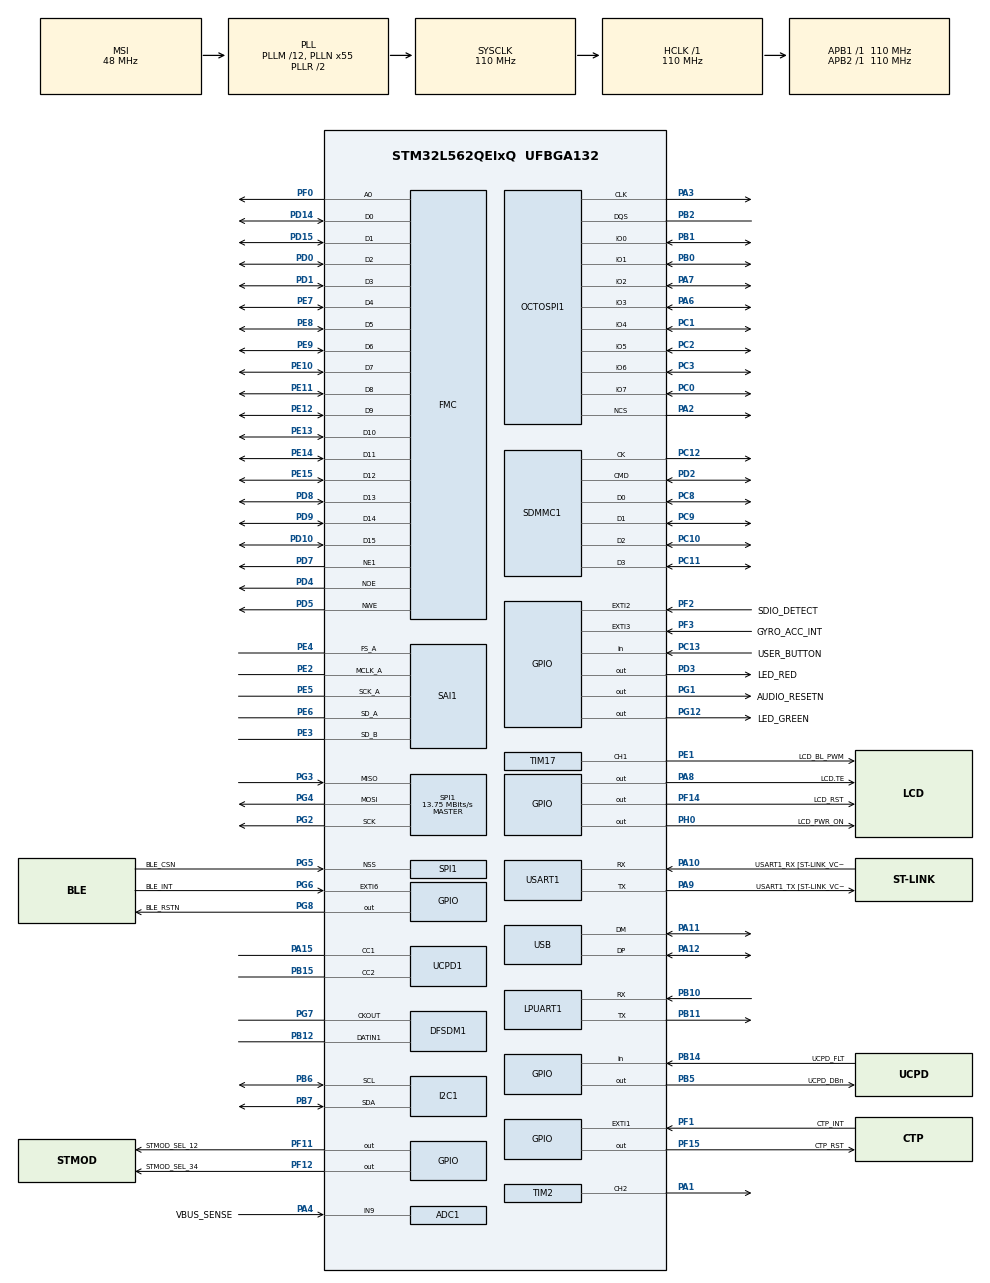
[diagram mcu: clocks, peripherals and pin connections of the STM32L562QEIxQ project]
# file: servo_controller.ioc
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ADC1.Channel-0\#ChannelRegularConversion=ADC_CHANNEL_9
ADC1.NbrOfConversionFlag=1
ADC1.OffsetNumber-0\#ChannelRegularConversion=ADC_OFFSET_NONE
ADC1.Rank-0\#ChannelRegularConversion=1
ADC1.SamplingTime-0\#ChannelRegularConversion=ADC_SAMPLETIME_2CYCLES_5
ADC1.master=1
I2C1.Timing=0x40505681
Mcu.Family=STM32L5
Mcu.Name=STM32L562QEIxQ
Mcu.Package=UFBGA132
Mcu.TrustZone=disable
NVIC.PriorityGroup=NVIC_PRIORITYGROUP_3
PA1.Signal=S_TIM2_CH2
PA10.GPIO_Label=USART1_RX [ST-LINK_VCP_TX]
PA10.Mode=Asynchronous
PA10.Signal=USART1_RX
PA11.Mode=Device
PA11.Signal=USB_DM
PA12.Mode=Device
PA12.Signal=USB_DP
PA13\ (JTMS/SWDIO).Mode=Trace_Asynchronous_SW
PA13\ (JTMS/SWDIO).Signal=DEBUG_JTMS-SWDIO
PA14\ (JTCK/SWCLK).Mode=Trace_Asynchronous_SW
PA14\ (JTCK/SWCLK).Signal=DEBUG_JTCK-SWCLK
PA15\ (JTDI).Mode=Source_AllSignals
PA15\ (JTDI).Signal=UCPD1_CC1
PA2.Mode=octods_mode
PA2.Signal=OCTOSPI1_NCS
PA3.Mode=octods_mode
PA3.Signal=OCTOSPI1_CLK
PA4.GPIO_Label=VBUS_SENSE
PA4.Signal=ADCx_IN9
PA6.Mode=octods_mode
PA6.Signal=OCTOSPI1_IO3
PA7.Mode=octods_mode
PA7.Signal=OCTOSPI1_IO2
PA8.GPIO_Label=LCD.TE
PA8.Signal=GPIO_Output
PA9.GPIO_Label=USART1_TX [ST-LINK_VCP_RX]
PA9.Mode=Asynchronous
PA9.Signal=USART1_TX
PB0.Mode=octods_mode
PB0.Signal=OCTOSPI1_IO1
PB1.Mode=octods_mode
PB1.Signal=OCTOSPI1_IO0
PB10.Mode=Asynchronous
PB10.Signal=LPUART1_RX
PB11.Mode=Asynchronous
PB11.Signal=LPUART1_TX
PB12.Signal=S_DATAIN1DFSDM1
PB14.GPIO_Label=UCPD_FLT
PB14.Signal=GPIO_Input
PB15.Mode=Source_AllSignals
PB15.Signal=UCPD1_CC2
PB2.Mode=octods_mode
PB2.Signal=OCTOSPI1_DQS
PB3\ (JTDO/TRACESWO).Mode=Trace_Asynchronous_SW
PB3\ (JTDO/TRACESWO).Signal=DEBUG_JTDO-SWO
PB5.GPIO_Label=UCPD_DBn
PB5.Signal=GPIO_Output
PB6.Mode=I2C
PB6.Signal=I2C1_SCL
PB7.Mode=I2C
PB7.Signal=I2C1_SDA
PC0.Mode=octods_mode
PC0.Signal=OCTOSPI1_IO7
PC1.Mode=octods_mode
PC1.Signal=OCTOSPI1_IO4
PC10.Mode=SD_4_bits_Wide_bus
PC10.Signal=SDMMC1_D2
PC11.Mode=SD_4_bits_Wide_bus
PC11.Signal=SDMMC1_D3
PC12.Mode=SD_4_bits_Wide_bus
PC12.Signal=SDMMC1_CK
PC13.GPIO_Label=USER_BUTTON
PC13.Signal=GPIO_Input
PC14-OSC32_IN\ (PC14).Mode=LSE-External-Oscillator
PC14-OSC32_IN\ (PC14).Signal=RCC_OSC32_IN
PC15-OSC32_OUT\ (PC15).Mode=LSE-External-Oscillator
PC15-OSC32_OUT\ (PC15).Signal=RCC_OSC32_OUT
PC2.Mode=octods_mode
PC2.Signal=OCTOSPI1_IO5
PC3.Mode=octods_mode
PC3.Signal=OCTOSPI1_IO6
PC8.Mode=SD_4_bits_Wide_bus
PC8.Signal=SDMMC1_D0
PC9.Mode=SD_4_bits_Wide_bus
PC9.Signal=SDMMC1_D1
PD0.Signal=FMC_D2_DA2
PD1.Signal=FMC_D3_DA3
PD10.Signal=FMC_D15_DA15
PD14.Signal=FMC_D0_DA0
PD15.Signal=FMC_D1_DA1
PD2.Mode=SD_4_bits_Wide_bus
PD2.Signal=SDMMC1_CMD
PD3.GPIO_Label=LED_RED
PD3.Signal=GPIO_Output
PD4.Signal=FMC_NOE
PD5.Signal=FMC_NWE
PD7.Mode=NorPsramChipSelect1_1
PD7.Signal=FMC_NE1
PD8.Signal=FMC_D13_DA13
PD9.Signal=FMC_D14_DA14
PE1.GPIO_Label=LCD_BL_PWM
PE1.Signal=S_TIM17_CH1
PE10.Signal=FMC_D7_DA7
PE11.Signal=FMC_D8_DA8
PE12.Signal=FMC_D9_DA9
PE13.Signal=FMC_D10_DA10
PE14.Signal=FMC_D11_DA11
PE15.Signal=FMC_D12_DA12
PE2.Mode=SAI_A_MasterWithClock
PE2.Signal=SAI1_MCLK_A
PE3.Mode=SAI_B_SPDIF
PE3.Signal=SAI1_SD_B
PE4.Mode=SAI_A_MasterWithClock
PE4.Signal=SAI1_FS_A
PE5.Mode=SAI_A_MasterWithClock
PE5.Signal=SAI1_SCK_A
PE6.Mode=SAI_A_MasterWithClock
PE6.Signal=SAI1_SD_A
PE7.Signal=FMC_D4_DA4
PE8.Signal=FMC_D5_DA5
PE9.Signal=FMC_D6_DA6
PF0.Signal=FMC_A0
PF1.GPIO_Label=CTP_INT
PF1.Signal=GPXTI1
PF11.GPIO_Label=STMOD_SEL_12
PF11.Signal=GPIO_Output
PF12.GPIO_Label=STMOD_SEL_34
PF12.Signal=GPIO_Output
PF14.GPIO_Label=LCD_RST
PF14.Signal=GPIO_Output
PF15.GPIO_Label=CTP_RST
PF15.Signal=GPIO_Output
PF2.GPIO_Label=SDIO_DETECT
PF2.Signal=GPXTI2
PF3.GPIO_Label=GYRO_ACC_INT
PF3.Signal=GPXTI3
PG1.GPIO_Label=AUDIO_RESETN
PG1.Signal=GPIO_Output
PG12.GPIO_Label=LED_GREEN
PG12.Signal=GPIO_Output
PG2.Mode=Full_Duplex_Master
PG2.Signal=SPI1_SCK
PG3.Mode=Full_Duplex_Master
PG3.Signal=SPI1_MISO
PG4.Mode=Full_Duplex_Master
PG4.Signal=SPI1_MOSI
PG5.GPIO_Label=BLE_CSN
PG5.Mode=NSS_Signal_Hard_Input
PG5.Signal=SPI1_NSS
PG6.GPIO_Label=BLE_INT
PG6.Signal=GPXTI6
PG7.Signal=S_CKOUTDFSDM1
PG8.GPIO_Label=BLE_RSTN
PG8.Signal=GPIO_Output
PH0-OSC_IN\ (PH0).GPIO_Label=LCD_PWR_ON
PH0-OSC_IN\ (PH0).Signal=GPIO_Output
ProjectManager.HeapSize=0x200
ProjectManager.StackSize=0x400
ProjectManager.TargetToolchain=EWARM V8.32
RCC.ADCFreq_Value=96000000
RCC.AHBFreq_Value=110000000
RCC.APB1Freq_Value=110000000
RCC.APB1TimFreq_Value=110000000
RCC.APB2Freq_Value=110000000
RCC.APB2TimFreq_Value=110000000
RCC.CK48CLockSelection=RCC_USBCLKSOURCE_MSI
RCC.CortexFreq_Value=110000000
RCC.HCLKFreq_Value=110000000
RCC.HSE_VALUE=8000000
RCC.HSI48_VALUE=48000000
RCC.HSI_VALUE=16000000
RCC.MSIClockRange=RCC_MSIRANGE_11
RCC.MSI_VALUE=48000000
RCC.PLLM=12
RCC.PLLN=55
RCC.PLLSAI1M=4
RCC.PLLSAI1N=48
RCC.PLLSAI1P=RCC_PLLP_DIV17
RCC.PLLSAI1Source=RCC_PLLSAI1SOURCE_HSI
RCC.SDMMCClockSelection=RCC_SDIOCLKSOURCE_CLK48
RCC.SYSCLKFreq_VALUE=110000000
RCC.SYSCLKSource=RCC_SYSCLKSOURCE_PLLCLK
RCC.USBFreq_Value=48000000
RCC.VCOOutputFreq_Value=220000000
SAI1.ErrorAudioFreq-SAI_A_MasterWithClock=-77.02 %
SAI1.Instance-SAI_A_MasterWithClock=SAI$Index_Block_A
SAI1.Instance-SAI_B_SPDIF=SAI$Index_Block_B
SAI1.MckOutput-SAI_A_MasterWithClock=SAI_MCK_OUTPUT_ENABLE
SAI1.RealAudioFreq-SAI_A_MasterWithClock=44.117 KHz
SAI1.RealAudioFreq-SAI_B_SPDIF=214.285 KHz
SAI1.VirtualMode-SAI_A_MasterWithClock=VM_MASTER
SAI1.VirtualMode-SAI_B_SPDIF=VM_SPDIF
SH.ADCx_IN9.0=ADC1_IN9,IN9-Single-Ended
SH.FMC_A0.0=FMC_A0,A0_1
SH.FMC_D0_DA0.0=FMC_DA0
SH.FMC_D0_DA0.1=FMC_D0,16b-d1
SH.FMC_D10_DA10.0=FMC_DA10
SH.FMC_D10_DA10.1=FMC_D10,16b-d1
SH.FMC_D11_DA11.0=FMC_DA11
SH.FMC_D11_DA11.1=FMC_D11,16b-d1
SH.FMC_D12_DA12.0=FMC_DA12
SH.FMC_D12_DA12.1=FMC_D12,16b-d1
SH.FMC_D13_DA13.0=FMC_DA13
SH.FMC_D13_DA13.1=FMC_D13,16b-d1
SH.FMC_D14_DA14.0=FMC_DA14
SH.FMC_D14_DA14.1=FMC_D14,16b-d1
SH.FMC_D15_DA15.0=FMC_DA15
SH.FMC_D15_DA15.1=FMC_D15,16b-d1
SH.FMC_D1_DA1.0=FMC_DA1
SH.FMC_D1_DA1.1=FMC_D1,16b-d1
SH.FMC_D2_DA2.0=FMC_DA2
SH.FMC_D2_DA2.1=FMC_D2,16b-d1
SH.FMC_D3_DA3.0=FMC_DA3
SH.FMC_D3_DA3.1=FMC_D3,16b-d1
SH.FMC_D4_DA4.0=FMC_DA4
SH.FMC_D4_DA4.1=FMC_D4,16b-d1
SH.FMC_D5_DA5.0=FMC_DA5
SH.FMC_D5_DA5.1=FMC_D5,16b-d1
SH.FMC_D6_DA6.0=FMC_DA6
SH.FMC_D6_DA6.1=FMC_D6,16b-d1
SH.FMC_D7_DA7.0=FMC_DA7
SH.FMC_D7_DA7.1=FMC_D7,16b-d1
SH.FMC_D8_DA8.0=FMC_DA8
SH.FMC_D8_DA8.1=FMC_D8,16b-d1
SH.FMC_D9_DA9.0=FMC_DA9
SH.FMC_D9_DA9.1=FMC_D9,16b-d1
SH.FMC_NOE.0=FMC_NOE,Lcd1
SH.FMC_NWE.0=FMC_NWE,Lcd1
SH.S_CKOUTDFSDM1.0=DFSDM1_CKOUT,CKOUT
SH.S_DATAIN1DFSDM1.0=DFSDM1_DATIN1,Manchester_input_from_ch1
SH.S_TIM17_CH1.0=TIM17_CH1,PWM Generation1 CH1
SH.S_TIM2_CH2.0=TIM2_CH2,PWM Generation2 CH2
SPI1.BaudRatePrescaler=SPI_BAUDRATEPRESCALER_8
SPI1.CalculateBaudRate=13.75 MBits/s
SPI1.Direction=SPI_DIRECTION_2LINES
SPI1.Mode=SPI_MODE_MASTER
SPI1.VirtualNSS=VM_NSSHARD
SPI1.VirtualType=VM_MASTER
TIM17.Channel=TIM_CHANNEL_1
TIM2.Channel-PWM\ Generation2\ CH2=TIM_CHANNEL_2
USART1.VirtualMode-Asynchronous=VM_ASYNC
VP_DFSDM1_VS_IN0.Mode=Parallel_Input_ch0
VP_DFSDM1_VS_IN2.Mode=Parallel_Input_ch2
VP_GTZC_VS_GTZC_Enable.Mode=GTZC_Enable
VP_PWR_VS_DBSignals.Mode=DisableDeadBatterySignals
VP_SYS_S_VS_Systick.Mode=SysTick
VP_TIM16_VS_ClockSourceINT.Mode=Enable_Timer
VP_TIM17_VS_ClockSourceINT.Mode=Enable_Timer
VP_TIM4_VS_ClockSourceITR.Mode=TriggerSource_ITR1
VP_TIM4_VS_ControllerModeClock.Mode=Clock Mode
board=STM32L562E-DK

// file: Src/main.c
/* USER CODE BEGIN Header */
/**
  ******************************************************************************
  * @file           : main.c
  * @brief          : Main program body
  ******************************************************************************
  * @attention
  *
  * <h2><center>&copy; Copyright (c) 2020 STMicroelectronics.
  * All rights reserved.</center></h2>
  *
  * This software component is licensed by ST under BSD 3-Clause license,
  * the "License"; You may not use this file except in compliance with the
  * License. You may obtain a copy of the License at:
  *                        opensource.org/licenses/BSD-3-Clause
  *
  ******************************************************************************
  */
/* USER CODE END Header */

#include "main.h"

/* USER CODE BEGIN Includes */
#include "stm32l552e_eval.h"
/* USER CODE END Includes */

ADC_HandleTypeDef hadc1;

DFSDM_Channel_HandleTypeDef hdfsdm1_channel0;
DFSDM_Channel_HandleTypeDef hdfsdm1_channel1;
DFSDM_Channel_HandleTypeDef hdfsdm1_channel2;

I2C_HandleTypeDef hi2c1;

UART_HandleTypeDef hlpuart1;
UART_HandleTypeDef huart1;

OSPI_HandleTypeDef hospi1;

SAI_HandleTypeDef hsai_BlockA1;
SAI_HandleTypeDef hsai_BlockB1;

SD_HandleTypeDef hsd1;

SPI_HandleTypeDef hspi1;

TIM_HandleTypeDef htim2;
TIM_HandleTypeDef htim4;
TIM_HandleTypeDef htim16;
TIM_HandleTypeDef htim17;

PCD_HandleTypeDef hpcd_USB_FS;

SRAM_HandleTypeDef hsram1;

void        SystemClock_Config(void);
void        PeriphCommonClock_Config(void);
static void MX_GPIO_Init(void);
static void MX_ADC1_Init(void);
static void MX_DFSDM1_Init(void);
static void MX_FMC_Init(void);
static void MX_GTZC_Init(void);
static void MX_I2C1_Init(void);
static void MX_LPUART1_UART_Init(void);
static void MX_USART1_UART_Init(void);
static void MX_OCTOSPI1_Init(void);
static void MX_SAI1_Init(void);
static void MX_SDMMC1_SD_Init(void);
static void MX_SPI1_Init(void);
static void MX_TIM2_Init(void);
static void MX_TIM4_Init(void);
static void MX_TIM16_Init(void);
static void MX_TIM17_Init(void);
static void MX_UCPD1_Init(void);
static void MX_USB_PCD_Init(void);

int main(void)
{

    /* MCU Configuration--------------------------------------------------------*/

    /* Reset of all peripherals, Initializes the Flash interface and the Systick. */
    HAL_Init();

    /* Configure the system clock */
    SystemClock_Config();

    /* Configure the peripherals common clocks */
    PeriphCommonClock_Config();

    /* GTZC initialisation */
    MX_GTZC_Init();

    /* Initialize all configured peripherals */
    MX_GPIO_Init();
    MX_ADC1_Init();
    MX_DFSDM1_Init();
    MX_FMC_Init();
    MX_I2C1_Init();
    MX_LPUART1_UART_Init();
    MX_USART1_UART_Init();
    MX_OCTOSPI1_Init();
    MX_SAI1_Init();
    MX_SDMMC1_SD_Init();
    MX_SPI1_Init();
    MX_TIM2_Init();
    MX_TIM4_Init();
    MX_TIM16_Init();
    MX_TIM17_Init();
    MX_UCPD1_Init();
    MX_USB_PCD_Init();
    /* USER CODE BEGIN 2 */
    /* Configure User push-button */
    BSP_PB_Init(BUTTON_KEY, BUTTON_MODE_GPIO);

    /* USER CODE END 2 */

    /* Infinite loop */
    while (1)
    {
        /* Check if the User push-button is pressed */
        if (BSP_PB_GetState(BUTTON_KEY) != GPIO_PIN_RESET)
        {
            /* Test +
        if user code is programmed starting from address 0x0800C000 */
            if (((*(__IO uint32_t *)USBD_DFU_APP_DEFAULT_ADD) & 0x2FFC0000) ==
                0x20000000)
            {
                /* Jump to user application */
                JumpAddress       = *(__IO uint32_t *)(USBD_DFU_APP_DEFAULT_ADD + 4);
                JumpToApplication = (pFunction)JumpAddress;

                /* Initialize user application's Stack Pointer */
                __set_MSP(*(__IO uint32_t *)USBD_DFU_APP_DEFAULT_ADD);
                JumpToApplication();
            }
        }
    }
}

void SystemClock_Config(void)
{
    RCC_OscInitTypeDef RCC_OscInitStruct = {0};
    RCC_ClkInitTypeDef RCC_ClkInitStruct = {0};

    /** Configure the main internal regulator output voltage
  */
    if (HAL_PWREx_ControlVoltageScaling(PWR_REGULATOR_VOLTAGE_SCALE0) != HAL_OK)
    {
        Error_Handler();
    }
    /** Configure LSE Drive Capability
  */
    HAL_PWR_EnableBkUpAccess();
    __HAL_RCC_LSEDRIVE_CONFIG(RCC_LSEDRIVE_LOW);
    /** Initializes the CPU, AHB and APB busses clocks
  */
    RCC_OscInitStruct.OscillatorType      = RCC_OSCILLATORTYPE_HSI | RCC_OSCILLATORTYPE_LSE | RCC_OSCILLATORTYPE_MSI;
    RCC_OscInitStruct.LSEState            = RCC_LSE_ON;
    RCC_OscInitStruct.HSIState            = RCC_HSI_ON;
    RCC_OscInitStruct.HSICalibrationValue = RCC_HSICALIBRATION_DEFAULT;
    RCC_OscInitStruct.MSIState            = RCC_MSI_ON;
    RCC_OscInitStruct.MSICalibrationValue = RCC_MSICALIBRATION_DEFAULT;
    RCC_OscInitStruct.MSIClockRange       = RCC_MSIRANGE_11;
    RCC_OscInitStruct.PLL.PLLState        = RCC_PLL_ON;
    RCC_OscInitStruct.PLL.PLLSource       = RCC_PLLSOURCE_MSI;
    RCC_OscInitStruct.PLL.PLLM            = 12;
    RCC_OscInitStruct.PLL.PLLN            = 55;
    RCC_OscInitStruct.PLL.PLLP            = RCC_PLLP_DIV7;
    RCC_OscInitStruct.PLL.PLLQ            = RCC_PLLQ_DIV2;
    RCC_OscInitStruct.PLL.PLLR            = RCC_PLLR_DIV2;
    if (HAL_RCC_OscConfig(&RCC_OscInitStruct) != HAL_OK)
    {
        Error_Handler();
    }
    /** Initializes the CPU, AHB and APB busses clocks
  */
    RCC_ClkInitStruct.ClockType      = RCC_CLOCKTYPE_HCLK | RCC_CLOCKTYPE_SYSCLK | RCC_CLOCKTYPE_PCLK1 | RCC_CLOCKTYPE_PCLK2;
    RCC_ClkInitStruct.SYSCLKSource   = RCC_SYSCLKSOURCE_PLLCLK;
    RCC_ClkInitStruct.AHBCLKDivider  = RCC_SYSCLK_DIV1;
    RCC_ClkInitStruct.APB1CLKDivider = RCC_HCLK_DIV1;
    RCC_ClkInitStruct.APB2CLKDivider = RCC_HCLK_DIV1;

    if (HAL_RCC_ClockConfig(&RCC_ClkInitStruct, FLASH_LATENCY_5) != HAL_OK)
    {
        Error_Handler();
    }
    /** Enable MSI Auto calibration
  */
    HAL_RCCEx_EnableMSIPLLMode();
}

void PeriphCommonClock_Config(void)
{
    RCC_PeriphCLKInitTypeDef PeriphClkInit = {0};

    /** Initializes the common periph clock
  */
    PeriphClkInit.PeriphClockSelection    = RCC_PERIPHCLK_ADC | RCC_PERIPHCLK_SAI1;
    PeriphClkInit.Sai1ClockSelection      = RCC_SAI1CLKSOURCE_PLLSAI1;
    PeriphClkInit.AdcClockSelection       = RCC_ADCCLKSOURCE_PLLSAI1;
    PeriphClkInit.PLLSAI1.PLLSAI1Source   = RCC_PLLSAI1SOURCE_HSI;
    PeriphClkInit.PLLSAI1.PLLSAI1M        = 4;
    PeriphClkInit.PLLSAI1.PLLSAI1N        = 48;
    PeriphClkInit.PLLSAI1.PLLSAI1P        = RCC_PLLP_DIV17;
    PeriphClkInit.PLLSAI1.PLLSAI1Q        = RCC_PLLQ_DIV2;
    PeriphClkInit.PLLSAI1.PLLSAI1R        = RCC_PLLR_DIV2;
    PeriphClkInit.PLLSAI1.PLLSAI1ClockOut = RCC_PLLSAI1_SAI1CLK | RCC_PLLSAI1_ADC1CLK;
    if (HAL_RCCEx_PeriphCLKConfig(&PeriphClkInit) != HAL_OK)
    {
        Error_Handler();
    }
}

static void MX_ADC1_Init(void)
{

    ADC_MultiModeTypeDef   multimode = {0};
    ADC_ChannelConfTypeDef sConfig   = {0};

    /** Common config
  */
    hadc1.Instance                   = ADC1;
    hadc1.Init.ClockPrescaler        = ADC_CLOCK_ASYNC_DIV1;
    hadc1.Init.Resolution            = ADC_RESOLUTION_12B;
    hadc1.Init.DataAlign             = ADC_DATAALIGN_RIGHT;
    hadc1.Init.ScanConvMode          = ADC_SCAN_DISABLE;
    hadc1.Init.EOCSelection          = ADC_EOC_SINGLE_CONV;
    hadc1.Init.LowPowerAutoWait      = DISABLE;
    hadc1.Init.ContinuousConvMode    = DISABLE;
    hadc1.Init.NbrOfConversion       = 1;
    hadc1.Init.DiscontinuousConvMode = DISABLE;
    hadc1.Init.NbrOfDiscConversion   = 1;
    hadc1.Init.ExternalTrigConv      = ADC_SOFTWARE_START;
    hadc1.Init.ExternalTrigConvEdge  = ADC_EXTERNALTRIGCONVEDGE_NONE;
    hadc1.Init.DMAContinuousRequests = DISABLE;
    hadc1.Init.Overrun               = ADC_OVR_DATA_PRESERVED;
    hadc1.Init.OversamplingMode      = DISABLE;
    if (HAL_ADC_Init(&hadc1) != HAL_OK)
    {
        Error_Handler();
    }
    /** Configure the ADC multi-mode
  */
    multimode.Mode = ADC_MODE_INDEPENDENT;
    if (HAL_ADCEx_MultiModeConfigChannel(&hadc1, &multimode) != HAL_OK)
    {
        Error_Handler();
    }
    /** Configure Regular Channel
  */
    sConfig.Channel      = ADC_CHANNEL_9;
    sConfig.Rank         = ADC_REGULAR_RANK_1;
    sConfig.SamplingTime = ADC_SAMPLETIME_2CYCLES_5;
    sConfig.SingleDiff   = ADC_SINGLE_ENDED;
    sConfig.OffsetNumber = ADC_OFFSET_NONE;
    sConfig.Offset       = 0;
    if (HAL_ADC_ConfigChannel(&hadc1, &sConfig) != HAL_OK)
    {
        Error_Handler();
    }
}

static void MX_DFSDM1_Init(void)
{

    hdfsdm1_channel0.Instance                      = DFSDM1_Channel0;
    hdfsdm1_channel0.Init.OutputClock.Activation   = ENABLE;
    hdfsdm1_channel0.Init.OutputClock.Selection    = DFSDM_CHANNEL_OUTPUT_CLOCK_SYSTEM;
    hdfsdm1_channel0.Init.OutputClock.Divider      = 2;
    hdfsdm1_channel0.Init.Input.Multiplexer        = DFSDM_CHANNEL_INTERNAL_REGISTER;
    hdfsdm1_channel0.Init.Input.DataPacking        = DFSDM_CHANNEL_STANDARD_MODE;
    hdfsdm1_channel0.Init.Input.Pins               = DFSDM_CHANNEL_SAME_CHANNEL_PINS;
    hdfsdm1_channel0.Init.SerialInterface.Type     = DFSDM_CHANNEL_SPI_RISING;
    hdfsdm1_channel0.Init.SerialInterface.SpiClock = DFSDM_CHANNEL_SPI_CLOCK_EXTERNAL;
    hdfsdm1_channel0.Init.Awd.FilterOrder          = DFSDM_CHANNEL_FASTSINC_ORDER;
    hdfsdm1_channel0.Init.Awd.Oversampling         = 1;
    hdfsdm1_channel0.Init.Offset                   = 0x00;
    hdfsdm1_channel0.Init.RightBitShift            = 0x00;
    if (HAL_DFSDM_ChannelInit(&hdfsdm1_channel0) != HAL_OK)
    {
        Error_Handler();
    }
    hdfsdm1_channel1.Instance                      = DFSDM1_Channel1;
    hdfsdm1_channel1.Init.OutputClock.Activation   = ENABLE;
    hdfsdm1_channel1.Init.OutputClock.Selection    = DFSDM_CHANNEL_OUTPUT_CLOCK_SYSTEM;
    hdfsdm1_channel1.Init.OutputClock.Divider      = 2;
    hdfsdm1_channel1.Init.Input.Multiplexer        = DFSDM_CHANNEL_EXTERNAL_INPUTS;
    hdfsdm1_channel1.Init.Input.DataPacking        = DFSDM_CHANNEL_STANDARD_MODE;
    hdfsdm1_channel1.Init.Input.Pins               = DFSDM_CHANNEL_SAME_CHANNEL_PINS;
    hdfsdm1_channel1.Init.SerialInterface.Type     = DFSDM_CHANNEL_MANCHESTER_RISING;
    hdfsdm1_channel1.Init.SerialInterface.SpiClock = DFSDM_CHANNEL_SPI_CLOCK_EXTERNAL;
    hdfsdm1_channel1.Init.Awd.FilterOrder          = DFSDM_CHANNEL_FASTSINC_ORDER;
    hdfsdm1_channel1.Init.Awd.Oversampling         = 1;
    hdfsdm1_channel1.Init.Offset                   = 0;
    hdfsdm1_channel1.Init.RightBitShift            = 0x00;
    if (HAL_DFSDM_ChannelInit(&hdfsdm1_channel1) != HAL_OK)
    {
        Error_Handler();
    }
    hdfsdm1_channel2.Instance                      = DFSDM1_Channel2;
    hdfsdm1_channel2.Init.OutputClock.Activation   = ENABLE;
    hdfsdm1_channel2.Init.OutputClock.Selection    = DFSDM_CHANNEL_OUTPUT_CLOCK_SYSTEM;
    hdfsdm1_channel2.Init.OutputClock.Divider      = 2;
    hdfsdm1_channel2.Init.Input.Multiplexer        = DFSDM_CHANNEL_INTERNAL_REGISTER;
    hdfsdm1_channel2.Init.Input.DataPacking        = DFSDM_CHANNEL_STANDARD_MODE;
    hdfsdm1_channel2.Init.Input.Pins               = DFSDM_CHANNEL_SAME_CHANNEL_PINS;
    hdfsdm1_channel2.Init.SerialInterface.Type     = DFSDM_CHANNEL_SPI_RISING;
    hdfsdm1_channel2.Init.SerialInterface.SpiClock = DFSDM_CHANNEL_SPI_CLOCK_EXTERNAL;
    hdfsdm1_channel2.Init.Awd.FilterOrder          = DFSDM_CHANNEL_FASTSINC_ORDER;
    hdfsdm1_channel2.Init.Awd.Oversampling         = 1;
    hdfsdm1_channel2.Init.Offset                   = 0x00;
    hdfsdm1_channel2.Init.RightBitShift            = 0x00;
    if (HAL_DFSDM_ChannelInit(&hdfsdm1_channel2) != HAL_OK)
    {
        Error_Handler();
    }
}

static void MX_GTZC_Init(void)
{

}

static void MX_I2C1_Init(void)
{

    hi2c1.Instance              = I2C1;
    hi2c1.Init.Timing           = 0x40505681;
    hi2c1.Init.OwnAddress1      = 0;
    hi2c1.Init.AddressingMode   = I2C_ADDRESSINGMODE_7BIT;
    hi2c1.Init.DualAddressMode  = I2C_DUALADDRESS_DISABLE;
    hi2c1.Init.OwnAddress2      = 0;
    hi2c1.Init.OwnAddress2Masks = I2C_OA2_NOMASK;
    hi2c1.Init.GeneralCallMode  = I2C_GENERALCALL_DISABLE;
    hi2c1.Init.NoStretchMode    = I2C_NOSTRETCH_DISABLE;
    if (HAL_I2C_Init(&hi2c1) != HAL_OK)
    {
        Error_Handler();
    }
    /** Configure Analogue filter
  */
    if (HAL_I2CEx_ConfigAnalogFilter(&hi2c1, I2C_ANALOGFILTER_ENABLE) != HAL_OK)
    {
        Error_Handler();
    }
    /** Configure Digital filter
  */
    if (HAL_I2CEx_ConfigDigitalFilter(&hi2c1, 0) != HAL_OK)
    {
        Error_Handler();
    }
}

static void MX_LPUART1_UART_Init(void)
{

    hlpuart1.Instance                    = LPUART1;
    hlpuart1.Init.BaudRate               = 209700;
    hlpuart1.Init.WordLength             = UART_WORDLENGTH_8B;
    hlpuart1.Init.StopBits               = UART_STOPBITS_1;
    hlpuart1.Init.Parity                 = UART_PARITY_NONE;
    hlpuart1.Init.Mode                   = UART_MODE_TX_RX;
    hlpuart1.Init.HwFlowCtl              = UART_HWCONTROL_NONE;
    hlpuart1.Init.OneBitSampling         = UART_ONE_BIT_SAMPLE_DISABLE;
    hlpuart1.Init.ClockPrescaler         = UART_PRESCALER_DIV1;
    hlpuart1.AdvancedInit.AdvFeatureInit = UART_ADVFEATURE_NO_INIT;
    hlpuart1.FifoMode                    = UART_FIFOMODE_DISABLE;
    if (HAL_UART_Init(&hlpuart1) != HAL_OK)
    {
        Error_Handler();
    }
    if (HAL_UARTEx_SetTxFifoThreshold(&hlpuart1, UART_TXFIFO_THRESHOLD_1_8) != HAL_OK)
    {
        Error_Handler();
    }
    if (HAL_UARTEx_SetRxFifoThreshold(&hlpuart1, UART_RXFIFO_THRESHOLD_1_8) != HAL_OK)
    {
        Error_Handler();
    }
    if (HAL_UARTEx_DisableFifoMode(&hlpuart1) != HAL_OK)
    {
        Error_Handler();
    }
}

static void MX_USART1_UART_Init(void)
{

    huart1.Instance                    = USART1;
    huart1.Init.BaudRate               = 115200;
    huart1.Init.WordLength             = UART_WORDLENGTH_8B;
    huart1.Init.StopBits               = UART_STOPBITS_1;
    huart1.Init.Parity                 = UART_PARITY_NONE;
    huart1.Init.Mode                   = UART_MODE_TX_RX;
    huart1.Init.HwFlowCtl              = UART_HWCONTROL_NONE;
    huart1.Init.OverSampling           = UART_OVERSAMPLING_16;
    huart1.Init.OneBitSampling         = UART_ONE_BIT_SAMPLE_DISABLE;
    huart1.Init.ClockPrescaler         = UART_PRESCALER_DIV1;
    huart1.AdvancedInit.AdvFeatureInit = UART_ADVFEATURE_NO_INIT;
    if (HAL_UART_Init(&huart1) != HAL_OK)
    {
        Error_Handler();
    }
    if (HAL_UARTEx_SetTxFifoThreshold(&huart1, UART_TXFIFO_THRESHOLD_1_8) != HAL_OK)
    {
        Error_Handler();
    }
    if (HAL_UARTEx_SetRxFifoThreshold(&huart1, UART_RXFIFO_THRESHOLD_1_8) != HAL_OK)
    {
        Error_Handler();
    }
    if (HAL_UARTEx_DisableFifoMode(&huart1) != HAL_OK)
    {
        Error_Handler();
    }
}

static void MX_OCTOSPI1_Init(void)
{

    /* OCTOSPI1 parameter configuration*/
    hospi1.Instance                   = OCTOSPI1;
    hospi1.Init.FifoThreshold         = 1;
    hospi1.Init.DualQuad              = HAL_OSPI_DUALQUAD_DISABLE;
    hospi1.Init.MemoryType            = HAL_OSPI_MEMTYPE_MICRON;
    hospi1.Init.DeviceSize            = 32;
    hospi1.Init.ChipSelectHighTime    = 1;
    hospi1.Init.FreeRunningClock      = HAL_OSPI_FREERUNCLK_DISABLE;
    hospi1.Init.ClockMode             = HAL_OSPI_CLOCK_MODE_0;
    hospi1.Init.WrapSize              = HAL_OSPI_WRAP_NOT_SUPPORTED;
    hospi1.Init.ClockPrescaler        = 1;
    hospi1.Init.SampleShifting        = HAL_OSPI_SAMPLE_SHIFTING_NONE;
    hospi1.Init.DelayHoldQuarterCycle = HAL_OSPI_DHQC_DISABLE;
    hospi1.Init.ChipSelectBoundary    = 0;
    hospi1.Init.DelayBlockBypass      = HAL_OSPI_DELAY_BLOCK_BYPASSED;
    hospi1.Init.Refresh               = 0;
    if (HAL_OSPI_Init(&hospi1) != HAL_OK)
    {
        Error_Handler();
    }
}

static void MX_SAI1_Init(void)
{

    hsai_BlockA1.Instance                    = SAI1_Block_A;
    hsai_BlockA1.Init.Protocol               = SAI_FREE_PROTOCOL;
    hsai_BlockA1.Init.AudioMode              = SAI_MODEMASTER_TX;
    hsai_BlockA1.Init.DataSize               = SAI_DATASIZE_8;
    hsai_BlockA1.Init.FirstBit               = SAI_FIRSTBIT_MSB;
    hsai_BlockA1.Init.ClockStrobing          = SAI_CLOCKSTROBING_FALLINGEDGE;
    hsai_BlockA1.Init.Synchro                = SAI_ASYNCHRONOUS;
    hsai_BlockA1.Init.OutputDrive            = SAI_OUTPUTDRIVE_DISABLE;
    hsai_BlockA1.Init.NoDivider              = SAI_MASTERDIVIDER_ENABLE;
    hsai_BlockA1.Init.FIFOThreshold          = SAI_FIFOTHRESHOLD_EMPTY;
    hsai_BlockA1.Init.AudioFrequency         = SAI_AUDIO_FREQUENCY_192K;
    hsai_BlockA1.Init.SynchroExt             = SAI_SYNCEXT_DISABLE;
    hsai_BlockA1.Init.MonoStereoMode         = SAI_STEREOMODE;
    hsai_BlockA1.Init.CompandingMode         = SAI_NOCOMPANDING;
    hsai_BlockA1.Init.TriState               = SAI_OUTPUT_NOTRELEASED;
    hsai_BlockA1.Init.PdmInit.Activation     = DISABLE;
    hsai_BlockA1.Init.PdmInit.MicPairsNbr    = 1;
    hsai_BlockA1.Init.PdmInit.ClockEnable    = SAI_PDM_CLOCK1_ENABLE;
    hsai_BlockA1.FrameInit.FrameLength       = 8;
    hsai_BlockA1.FrameInit.ActiveFrameLength = 1;
    hsai_BlockA1.FrameInit.FSDefinition      = SAI_FS_STARTFRAME;
    hsai_BlockA1.FrameInit.FSPolarity        = SAI_FS_ACTIVE_LOW;
    hsai_BlockA1.FrameInit.FSOffset          = SAI_FS_FIRSTBIT;
    hsai_BlockA1.SlotInit.FirstBitOffset     = 0;
    hsai_BlockA1.SlotInit.SlotSize           = SAI_SLOTSIZE_DATASIZE;
    hsai_BlockA1.SlotInit.SlotNumber         = 1;
    hsai_BlockA1.SlotInit.SlotActive         = 0x00000000;
    if (HAL_SAI_Init(&hsai_BlockA1) != HAL_OK)
    {
        Error_Handler();
    }
    hsai_BlockB1.Instance                 = SAI1_Block_B;
    hsai_BlockB1.Init.Protocol            = SAI_SPDIF_PROTOCOL;
    hsai_BlockB1.Init.AudioMode           = SAI_MODEMASTER_TX;
    hsai_BlockB1.Init.Synchro             = SAI_ASYNCHRONOUS;
    hsai_BlockB1.Init.OutputDrive         = SAI_OUTPUTDRIVE_DISABLE;
    hsai_BlockB1.Init.FIFOThreshold       = SAI_FIFOTHRESHOLD_EMPTY;
    hsai_BlockB1.Init.AudioFrequency      = SAI_AUDIO_FREQUENCY_48K;
    hsai_BlockB1.Init.SynchroExt          = SAI_SYNCEXT_DISABLE;
    hsai_BlockB1.Init.MonoStereoMode      = SAI_STEREOMODE;
    hsai_BlockB1.Init.CompandingMode      = SAI_NOCOMPANDING;
    hsai_BlockB1.Init.PdmInit.Activation  = DISABLE;
    hsai_BlockB1.Init.PdmInit.MicPairsNbr = 1;
    hsai_BlockB1.Init.PdmInit.ClockEnable = SAI_PDM_CLOCK1_ENABLE;
    if (HAL_SAI_Init(&hsai_BlockB1) != HAL_OK)
    {
        Error_Handler();
    }
}

static void MX_SDMMC1_SD_Init(void)
{

    hsd1.Instance                 = SDMMC1;
    hsd1.Init.ClockEdge           = SDMMC_CLOCK_EDGE_RISING;
    hsd1.Init.ClockPowerSave      = SDMMC_CLOCK_POWER_SAVE_DISABLE;
    hsd1.Init.BusWide             = SDMMC_BUS_WIDE_4B;
    hsd1.Init.HardwareFlowControl = SDMMC_HARDWARE_FLOW_CONTROL_DISABLE;
    hsd1.Init.ClockDiv            = 0;
    hsd1.Init.TranceiverPresent   = SDMMC_TRANSCEIVER_NOT_PRESENT;
    if (HAL_SD_Init(&hsd1) != HAL_OK)
    {
        Error_Handler();
    }
}

static void MX_SPI1_Init(void)
{

    /* SPI1 parameter configuration*/
    hspi1.Instance               = SPI1;
    hspi1.Init.Mode              = SPI_MODE_MASTER;
    hspi1.Init.Direction         = SPI_DIRECTION_2LINES;
    hspi1.Init.DataSize          = SPI_DATASIZE_4BIT;
    hspi1.Init.CLKPolarity       = SPI_POLARITY_LOW;
    hspi1.Init.CLKPhase          = SPI_PHASE_1EDGE;
    hspi1.Init.NSS               = SPI_NSS_HARD_INPUT;
    hspi1.Init.BaudRatePrescaler = SPI_BAUDRATEPRESCALER_8;
    hspi1.Init.FirstBit          = SPI_FIRSTBIT_MSB;
    hspi1.Init.TIMode            = SPI_TIMODE_DISABLE;
    hspi1.Init.CRCCalculation    = SPI_CRCCALCULATION_DISABLE;
    hspi1.Init.CRCPolynomial     = 7;
    hspi1.Init.CRCLength         = SPI_CRC_LENGTH_DATASIZE;
    hspi1.Init.NSSPMode          = SPI_NSS_PULSE_ENABLE;
    if (HAL_SPI_Init(&hspi1) != HAL_OK)
    {
        Error_Handler();
    }
}

static void MX_TIM2_Init(void)
{

    TIM_MasterConfigTypeDef sMasterConfig = {0};
    TIM_OC_InitTypeDef      sConfigOC     = {0};

    htim2.Instance               = TIM2;
    htim2.Init.Prescaler         = 0;
    htim2.Init.CounterMode       = TIM_COUNTERMODE_UP;
    htim2.Init.Period            = 0;
    htim2.Init.ClockDivision     = TIM_CLOCKDIVISION_DIV1;
    htim2.Init.AutoReloadPreload = TIM_AUTORELOAD_PRELOAD_DISABLE;
    if (HAL_TIM_PWM_Init(&htim2) != HAL_OK)
    {
        Error_Handler();
    }
    sMasterConfig.MasterOutputTrigger = TIM_TRGO_RESET;
    sMasterConfig.MasterSlaveMode     = TIM_MASTERSLAVEMODE_DISABLE;
    if (HAL_TIMEx_MasterConfigSynchronization(&htim2, &sMasterConfig) != HAL_OK)
    {
        Error_Handler();
    }
    sConfigOC.OCMode     = TIM_OCMODE_PWM1;
    sConfigOC.Pulse      = 0;
    sConfigOC.OCPolarity = TIM_OCPOLARITY_HIGH;
    sConfigOC.OCFastMode = TIM_OCFAST_DISABLE;
    if (HAL_TIM_PWM_ConfigChannel(&htim2, &sConfigOC, TIM_CHANNEL_2) != HAL_OK)
    {
        Error_Handler();
    }
    HAL_TIM_MspPostInit(&htim2);
}

static void MX_TIM4_Init(void)
{

    TIM_SlaveConfigTypeDef  sSlaveConfig  = {0};
    TIM_MasterConfigTypeDef sMasterConfig = {0};

    htim4.Instance               = TIM4;
    htim4.Init.Prescaler         = 0;
    htim4.Init.CounterMode       = TIM_COUNTERMODE_UP;
    htim4.Init.Period            = 0;
    htim4.Init.ClockDivision     = TIM_CLOCKDIVISION_DIV1;
    htim4.Init.AutoReloadPreload = TIM_AUTORELOAD_PRELOAD_DISABLE;
    if (HAL_TIM_Base_Init(&htim4) != HAL_OK)
    {
        Error_Handler();
    }
    sSlaveConfig.SlaveMode    = TIM_SLAVEMODE_EXTERNAL1;
    sSlaveConfig.InputTrigger = TIM_TS_ITR1;
    if (HAL_TIM_SlaveConfigSynchro(&htim4, &sSlaveConfig) != HAL_OK)
    {
        Error_Handler();
    }
    sMasterConfig.MasterOutputTrigger = TIM_TRGO_RESET;
    sMasterConfig.MasterSlaveMode     = TIM_MASTERSLAVEMODE_DISABLE;
    if (HAL_TIMEx_MasterConfigSynchronization(&htim4, &sMasterConfig) != HAL_OK)
    {
        Error_Handler();
    }
}

static void MX_TIM16_Init(void)
{

    htim16.Instance               = TIM16;
    htim16.Init.Prescaler         = 0;
    htim16.Init.CounterMode       = TIM_COUNTERMODE_UP;
    htim16.Init.Period            = 0;
    htim16.Init.ClockDivision     = TIM_CLOCKDIVISION_DIV1;
    htim16.Init.RepetitionCounter = 0;
    htim16.Init.AutoReloadPreload = TIM_AUTORELOAD_PRELOAD_DISABLE;
    if (HAL_TIM_Base_Init(&htim16) != HAL_OK)
    {
        Error_Handler();
    }
}

static void MX_TIM17_Init(void)
{

    TIM_OC_InitTypeDef             sConfigOC            = {0};
    TIM_BreakDeadTimeConfigTypeDef sBreakDeadTimeConfig = {0};

    htim17.Instance               = TIM17;
    htim17.Init.Prescaler         = 0;
    htim17.Init.CounterMode       = TIM_COUNTERMODE_UP;
    htim17.Init.Period            = 0;
    htim17.Init.ClockDivision     = TIM_CLOCKDIVISION_DIV1;
    htim17.Init.RepetitionCounter = 0;
    htim17.Init.AutoReloadPreload = TIM_AUTORELOAD_PRELOAD_DISABLE;
    if (HAL_TIM_Base_Init(&htim17) != HAL_OK)
    {
        Error_Handler();
    }
    if (HAL_TIM_PWM_Init(&htim17) != HAL_OK)
    {
        Error_Handler();
    }
    sConfigOC.OCMode       = TIM_OCMODE_PWM1;
    sConfigOC.Pulse        = 0;
    sConfigOC.OCPolarity   = TIM_OCPOLARITY_HIGH;
    sConfigOC.OCNPolarity  = TIM_OCNPOLARITY_HIGH;
    sConfigOC.OCFastMode   = TIM_OCFAST_DISABLE;
    sConfigOC.OCIdleState  = TIM_OCIDLESTATE_RESET;
    sConfigOC.OCNIdleState = TIM_OCNIDLESTATE_RESET;
    if (HAL_TIM_PWM_ConfigChannel(&htim17, &sConfigOC, TIM_CHANNEL_1) != HAL_OK)
    {
        Error_Handler();
    }
    sBreakDeadTimeConfig.OffStateRunMode  = TIM_OSSR_DISABLE;
    sBreakDeadTimeConfig.OffStateIDLEMode = TIM_OSSI_DISABLE;
    sBreakDeadTimeConfig.LockLevel        = TIM_LOCKLEVEL_OFF;
    sBreakDeadTimeConfig.DeadTime         = 0;
    sBreakDeadTimeConfig.BreakState       = TIM_BREAK_DISABLE;
    sBreakDeadTimeConfig.BreakPolarity    = TIM_BREAKPOLARITY_HIGH;
    sBreakDeadTimeConfig.BreakFilter      = 0;
    sBreakDeadTimeConfig.AutomaticOutput  = TIM_AUTOMATICOUTPUT_DISABLE;
    if (HAL_TIMEx_ConfigBreakDeadTime(&htim17, &sBreakDeadTimeConfig) != HAL_OK)
    {
        Error_Handler();
    }
    HAL_TIM_MspPostInit(&htim17);
}

static void MX_UCPD1_Init(void)
{

    LL_GPIO_InitTypeDef GPIO_InitStruct = {0};

    /* Peripheral clock enable */
    LL_APB1_GRP2_EnableClock(LL_APB1_GRP2_PERIPH_UCPD1);

    LL_AHB2_GRP1_EnableClock(LL_AHB2_GRP1_PERIPH_GPIOA);
    LL_AHB2_GRP1_EnableClock(LL_AHB2_GRP1_PERIPH_GPIOB);
    /**UCPD1 GPIO Configuration
  PA15 (JTDI)   ------> UCPD1_CC1
  PB15   ------> UCPD1_CC2
  */
    GPIO_InitStruct.Pin  = LL_GPIO_PIN_15;
    GPIO_InitStruct.Mode = LL_GPIO_MODE_ANALOG;
    GPIO_InitStruct.Pull = LL_GPIO_PULL_NO;
    LL_GPIO_Init(GPIOA, &GPIO_InitStruct);

    GPIO_InitStruct.Pin  = LL_GPIO_PIN_15;
    GPIO_InitStruct.Mode = LL_GPIO_MODE_ANALOG;
    GPIO_InitStruct.Pull = LL_GPIO_PULL_NO;
    LL_GPIO_Init(GPIOB, &GPIO_InitStruct);

}

static void MX_USB_PCD_Init(void)
{

    hpcd_USB_FS.Instance                     = USB;
    hpcd_USB_FS.Init.dev_endpoints           = 8;
    hpcd_USB_FS.Init.speed                   = PCD_SPEED_FULL;
    hpcd_USB_FS.Init.phy_itface              = PCD_PHY_EMBEDDED;
    hpcd_USB_FS.Init.Sof_enable              = DISABLE;
    hpcd_USB_FS.Init.low_power_enable        = DISABLE;
    hpcd_USB_FS.Init.lpm_enable              = DISABLE;
    hpcd_USB_FS.Init.battery_charging_enable = DISABLE;
    if (HAL_PCD_Init(&hpcd_USB_FS) != HAL_OK)
    {
        Error_Handler();
    }
}

/* FMC initialization function */
static void MX_FMC_Init(void)
{

    FMC_NORSRAM_TimingTypeDef Timing = {0};

    /** Perform the SRAM1 memory initialization sequence
  */
    hsram1.Instance = FMC_NORSRAM_DEVICE;
    hsram1.Extended = FMC_NORSRAM_EXTENDED_DEVICE;
    /* hsram1.Init */
    hsram1.Init.NSBank             = FMC_NORSRAM_BANK1;
    hsram1.Init.DataAddressMux     = FMC_DATA_ADDRESS_MUX_DISABLE;
    hsram1.Init.MemoryType         = FMC_MEMORY_TYPE_SRAM;
    hsram1.Init.MemoryDataWidth    = FMC_NORSRAM_MEM_BUS_WIDTH_16;
    hsram1.Init.BurstAccessMode    = FMC_BURST_ACCESS_MODE_DISABLE;
    hsram1.Init.WaitSignalPolarity = FMC_WAIT_SIGNAL_POLARITY_LOW;
    hsram1.Init.WaitSignalActive   = FMC_WAIT_TIMING_BEFORE_WS;
    hsram1.Init.WriteOperation     = FMC_WRITE_OPERATION_ENABLE;
    hsram1.Init.WaitSignal         = FMC_WAIT_SIGNAL_DISABLE;
    hsram1.Init.ExtendedMode       = FMC_EXTENDED_MODE_DISABLE;
    hsram1.Init.AsynchronousWait   = FMC_ASYNCHRONOUS_WAIT_DISABLE;
    hsram1.Init.WriteBurst         = FMC_WRITE_BURST_DISABLE;
    hsram1.Init.ContinuousClock    = FMC_CONTINUOUS_CLOCK_SYNC_ONLY;
    hsram1.Init.WriteFifo          = FMC_WRITE_FIFO_ENABLE;
    hsram1.Init.NBLSetupTime       = 0;
    hsram1.Init.PageSize           = FMC_PAGE_SIZE_NONE;
    hsram1.Init.MaxChipSelectPulse = DISABLE;
    /* Timing */
    Timing.AddressSetupTime      = 15;
    Timing.AddressHoldTime       = 15;
    Timing.DataSetupTime         = 255;
    Timing.DataHoldTime          = 0;
    Timing.BusTurnAroundDuration = 15;
    Timing.CLKDivision           = 16;
    Timing.DataLatency           = 17;
    Timing.AccessMode            = FMC_ACCESS_MODE_A;
    /* ExtTiming */

    if (HAL_SRAM_Init(&hsram1, &Timing, NULL) != HAL_OK)
    {
        Error_Handler();
    }

}

static void MX_GPIO_Init(void)
{
    GPIO_InitTypeDef GPIO_InitStruct = {0};

    /* GPIO Ports Clock Enable */
    __HAL_RCC_GPIOE_CLK_ENABLE();
    __HAL_RCC_GPIOB_CLK_ENABLE();
    __HAL_RCC_GPIOG_CLK_ENABLE();
    HAL_PWREx_EnableVddIO2();
    __HAL_RCC_GPIOD_CLK_ENABLE();
    __HAL_RCC_GPIOC_CLK_ENABLE();
    __HAL_RCC_GPIOA_CLK_ENABLE();
    __HAL_RCC_GPIOF_CLK_ENABLE();
    __HAL_RCC_GPIOH_CLK_ENABLE();

    /*Configure GPIO pin Output Level */
    HAL_GPIO_WritePin(GPIOG, LED_GREEN_Pin | BLE_RSTN_Pin | AUDIO_RESETN_Pin, GPIO_PIN_RESET);

    /*Configure GPIO pin Output Level */
    HAL_GPIO_WritePin(LED_RED_GPIO_Port, LED_RED_Pin, GPIO_PIN_RESET);

    /*Configure GPIO pin Output Level */
    HAL_GPIO_WritePin(UCPD_DBn_GPIO_Port, UCPD_DBn_Pin, GPIO_PIN_RESET);

    /*Configure GPIO pin Output Level */
    HAL_GPIO_WritePin(LCD_TE_GPIO_Port, LCD_TE_Pin, GPIO_PIN_RESET);

    /*Configure GPIO pin Output Level */
    HAL_GPIO_WritePin(LCD_PWR_ON_GPIO_Port, LCD_PWR_ON_Pin, GPIO_PIN_RESET);

    /*Configure GPIO pin Output Level */
    HAL_GPIO_WritePin(GPIOF, LCD_RST_Pin | STMOD_SEL_12_Pin | STMOD_SEL_34_Pin | CTP_RST_Pin, GPIO_PIN_RESET);

    /*Configure GPIO pins : LED_GREEN_Pin BLE_RSTN_Pin AUDIO_RESETN_Pin */
    GPIO_InitStruct.Pin   = LED_GREEN_Pin | BLE_RSTN_Pin | AUDIO_RESETN_Pin;
    GPIO_InitStruct.Mode  = GPIO_MODE_OUTPUT_PP;
    GPIO_InitStruct.Pull  = GPIO_NOPULL;
    GPIO_InitStruct.Speed = GPIO_SPEED_FREQ_LOW;
    HAL_GPIO_Init(GPIOG, &GPIO_InitStruct);

    /*Configure GPIO pin : USER_BUTTON_Pin */
    GPIO_InitStruct.Pin  = USER_BUTTON_Pin;
    GPIO_InitStruct.Mode = GPIO_MODE_INPUT;
    GPIO_InitStruct.Pull = GPIO_NOPULL;
    HAL_GPIO_Init(USER_BUTTON_GPIO_Port, &GPIO_InitStruct);

    /*Configure GPIO pin : LED_RED_Pin */
    GPIO_InitStruct.Pin   = LED_RED_Pin;
    GPIO_InitStruct.Mode  = GPIO_MODE_OUTPUT_PP;
    GPIO_InitStruct.Pull  = GPIO_NOPULL;
    GPIO_InitStruct.Speed = GPIO_SPEED_FREQ_LOW;
    HAL_GPIO_Init(LED_RED_GPIO_Port, &GPIO_InitStruct);

    /*Configure GPIO pins : GYRO_ACC_INT_Pin SDIO_DETECT_Pin CTP_INT_Pin */
    GPIO_InitStruct.Pin  = GYRO_ACC_INT_Pin | SDIO_DETECT_Pin | CTP_INT_Pin;
    GPIO_InitStruct.Mode = GPIO_MODE_IT_RISING;
    GPIO_InitStruct.Pull = GPIO_NOPULL;
    HAL_GPIO_Init(GPIOF, &GPIO_InitStruct);

    /*Configure GPIO pin : UCPD_DBn_Pin */
    GPIO_InitStruct.Pin   = UCPD_DBn_Pin;
    GPIO_InitStruct.Mode  = GPIO_MODE_OUTPUT_PP;
    GPIO_InitStruct.Pull  = GPIO_NOPULL;
    GPIO_InitStruct.Speed = GPIO_SPEED_FREQ_LOW;
    HAL_GPIO_Init(UCPD_DBn_GPIO_Port, &GPIO_InitStruct);

    /*Configure GPIO pin : LCD_TE_Pin */
    GPIO_InitStruct.Pin   = LCD_TE_Pin;
    GPIO_InitStruct.Mode  = GPIO_MODE_OUTPUT_PP;
    GPIO_InitStruct.Pull  = GPIO_NOPULL;
    GPIO_InitStruct.Speed = GPIO_SPEED_FREQ_LOW;
    HAL_GPIO_Init(LCD_TE_GPIO_Port, &GPIO_InitStruct);

    /*Configure GPIO pin : LCD_PWR_ON_Pin */
    GPIO_InitStruct.Pin   = LCD_PWR_ON_Pin;
    GPIO_InitStruct.Mode  = GPIO_MODE_OUTPUT_PP;
    GPIO_InitStruct.Pull  = GPIO_NOPULL;
    GPIO_InitStruct.Speed = GPIO_SPEED_FREQ_LOW;
    HAL_GPIO_Init(LCD_PWR_ON_GPIO_Port, &GPIO_InitStruct);

    /*Configure GPIO pin : BLE_INT_Pin */
    GPIO_InitStruct.Pin  = BLE_INT_Pin;
    GPIO_InitStruct.Mode = GPIO_MODE_IT_RISING;
    GPIO_InitStruct.Pull = GPIO_NOPULL;
    HAL_GPIO_Init(BLE_INT_GPIO_Port, &GPIO_InitStruct);

    /*Configure GPIO pins : LCD_RST_Pin STMOD_SEL_12_Pin STMOD_SEL_34_Pin CTP_RST_Pin */
    GPIO_InitStruct.Pin   = LCD_RST_Pin | STMOD_SEL_12_Pin | STMOD_SEL_34_Pin | CTP_RST_Pin;
    GPIO_InitStruct.Mode  = GPIO_MODE_OUTPUT_PP;
    GPIO_InitStruct.Pull  = GPIO_NOPULL;
    GPIO_InitStruct.Speed = GPIO_SPEED_FREQ_LOW;
    HAL_GPIO_Init(GPIOF, &GPIO_InitStruct);

    /*Configure GPIO pin : UCPD_FLT_Pin */
    GPIO_InitStruct.Pin  = UCPD_FLT_Pin;
    GPIO_InitStruct.Mode = GPIO_MODE_INPUT;
    GPIO_InitStruct.Pull = GPIO_NOPULL;
    HAL_GPIO_Init(UCPD_FLT_GPIO_Port, &GPIO_InitStruct);
}

void Error_Handler(void)
{
}

/************************ (C) COPYRIGHT STMicroelectronics *****END OF FILE****/
